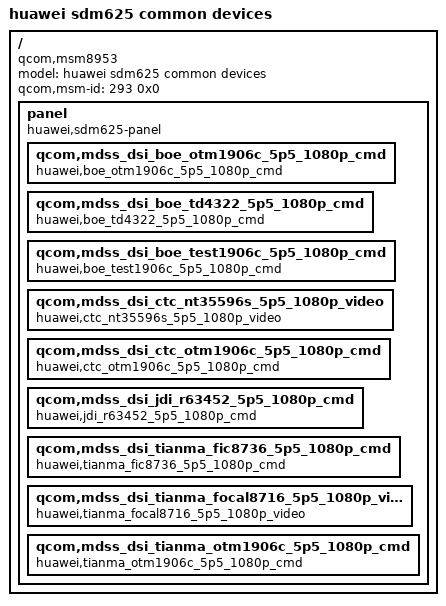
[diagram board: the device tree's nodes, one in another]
/*======================妈的华为毁我童年=========================*/
/*华为的device-tree写的特别乱，自己改的时候注意一点,不要被华为坑了，*/
/*一个型号比如麦芒5MLA-AL00给我整4，5个设备树，自己移植一定要注意别弄错了*/
/*写设备树的哥们，老子日你他妈，代码写的一团糟，我移植到主线kernel一堆bug,*/
/*是不是NT，是的话早点滚蛋，别让人适配起来一堆bug，工作量激增，写的sb board-id*/
/*快把我搞晕了，不想好好写早点滚蛋                                   */
/*
       　  　▃▆█▇▄▖
　 　 　 ▟◤▖　　　◥█▎
   　 ◢◤　 ▐　　　 　▐▉
　 ▗◤　　　▂　▗▖　　▕█▎
　◤　▗▅▖◥▄　▀◣　　█▊
▐　▕▎◥▖◣◤　　　　◢██
█◣　◥▅█▀　　　　▐██◤
▐█▙▂　　     　◢██◤
◥██◣　　　　◢▄◤
 　　▀██▅▇▀
哲学114514 */
/*==========================================================*/
/*English: That tip is only for chinese huawei, it realy Useless*/
/ {
  model = "huawei sdm625 common devices";
	compatible = "qcom,msm8953";
	qcom,msm-id = <293 0x0>;
  	panel {
		compatible = "huawei,sdm625-panel";
		qcom,mdss_dsi_boe_otm1906c_5p5_1080p_cmd {
			compatible = "huawei,boe_otm1906c_5p5_1080p_cmd";
		};
		qcom,mdss_dsi_boe_td4322_5p5_1080p_cmd {
			compatible = "huawei,boe_td4322_5p5_1080p_cmd";
		};
		qcom,mdss_dsi_boe_test1906c_5p5_1080p_cmd {
			compatible = "huawei,boe_test1906c_5p5_1080p_cmd";
		};
    qcom,mdss_dsi_ctc_nt35596s_5p5_1080p_video{
      compatible = "huawei,ctc_nt35596s_5p5_1080p_video";
    };
    qcom,mdss_dsi_ctc_otm1906c_5p5_1080p_cmd{
      compatible = "huawei,ctc_otm1906c_5p5_1080p_cmd";
    };
    qcom,mdss_dsi_jdi_r63452_5p5_1080p_cmd{
      compatible = "huawei,jdi_r63452_5p5_1080p_cmd";
    };
    qcom,mdss_dsi_tianma_fic8736_5p5_1080p_cmd{
      compatible = "huawei,tianma_fic8736_5p5_1080p_cmd";
    };
    qcom,mdss_dsi_tianma_focal8716_5p5_1080p_video{
      compatible = "huawei,tianma_focal8716_5p5_1080p_video";
    };
    qcom,mdss_dsi_tianma_otm1906c_5p5_1080p_cmd{
      compatible = "huawei,tianma_otm1906c_5p5_1080p_cmd";
    };
	};
};
